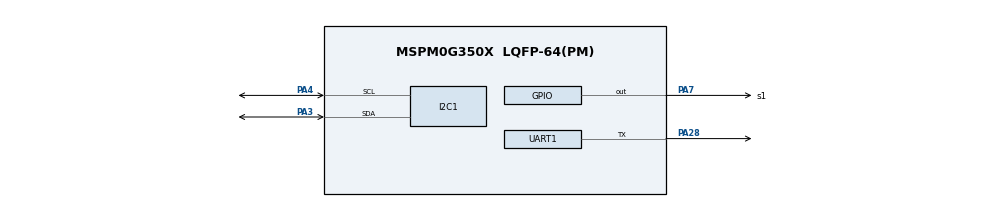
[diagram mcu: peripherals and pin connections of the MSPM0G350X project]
/**
 * @cliArgs --device "MSPM0G350X" --part "Default" --package "LQFP-64(PM)" --product "mspm0_sdk@2.10.00.04"
 * @versions {"tool":"1.27.1+4634"}
 */

/**
 * Import the modules used in this configuration.
 */
const ADC12         = scripting.addModule("/ti/driverlib/ADC12", {}, false);
const ADC121        = ADC12.addInstance();
const ADC122        = ADC12.addInstance();
const GPIO          = scripting.addModule("/ti/driverlib/GPIO", {}, false);
const GPIO1         = GPIO.addInstance();
const I2C           = scripting.addModule("/ti/driverlib/I2C", {}, false);
const I2C1          = I2C.addInstance();
const SYSCTL        = scripting.addModule("/ti/driverlib/SYSCTL");
const TIMER         = scripting.addModule("/ti/driverlib/TIMER", {}, false);
const TIMER1        = TIMER.addInstance();
const UART          = scripting.addModule("/ti/driverlib/UART", {}, false);
const UART1         = UART.addInstance();
const ProjectConfig = scripting.addModule("/ti/project_config/ProjectConfig");

/**
 * Write custom configuration values to the imported modules.
 */
ADC121.samplingOperationMode             = "sequence";
ADC121.endAdd                            = 3;
ADC121.adcMem0chansel                    = "DL_ADC12_INPUT_CHAN_5";
ADC121.adcMem1chansel                    = "DL_ADC12_INPUT_CHAN_6";
ADC121.adcMem2chansel                    = "DL_ADC12_INPUT_CHAN_7";
ADC121.adcMem3chansel                    = "DL_ADC12_INPUT_CHAN_8";
ADC121.enabledInterrupts                 = ["DL_ADC12_INTERRUPT_MEM3_RESULT_LOADED"];
ADC121.$name                             = "ADC12_1";
ADC121.sampClkDiv                        = "DL_ADC12_CLOCK_DIVIDE_48";
ADC121.trigSrc                           = "DL_ADC12_TRIG_SRC_EVENT";
ADC121.subChanID                         = 2;
ADC121.adcMem0_name                      = "s8";
ADC121.adcMem1_name                      = "s7";
ADC121.adcMem2_name                      = "s6";
ADC121.adcMem3_name                      = "s5";
ADC121.adcPin5Config.hideOutputInversion = scripting.forceWrite(false);
ADC121.adcPin5Config.$name               = "ti_driverlib_gpio_GPIOPinGeneric2";
ADC121.adcPin6Config.hideOutputInversion = scripting.forceWrite(false);
ADC121.adcPin6Config.$name               = "ti_driverlib_gpio_GPIOPinGeneric3";
ADC121.adcPin7Config.hideOutputInversion = scripting.forceWrite(false);
ADC121.adcPin7Config.$name               = "ti_driverlib_gpio_GPIOPinGeneric4";
ADC121.adcPin8Config.$name               = "ti_driverlib_gpio_GPIOPinGeneric0";
ADC121.adcPin8Config.hideOutputInversion = scripting.forceWrite(false);

ADC122.samplingOperationMode             = "sequence";
ADC122.endAdd                            = 3;
ADC122.adcMem0_name                      = "s1";
ADC122.adcMem1_name                      = "s2";
ADC122.adcMem1chansel                    = "DL_ADC12_INPUT_CHAN_1";
ADC122.adcMem2_name                      = "s3";
ADC122.adcMem2chansel                    = "DL_ADC12_INPUT_CHAN_2";
ADC122.adcMem3_name                      = "s4";
ADC122.adcMem3chansel                    = "DL_ADC12_INPUT_CHAN_3";
ADC122.enabledInterrupts                 = ["DL_ADC12_INTERRUPT_MEM3_RESULT_LOADED"];
ADC122.$name                             = "ADC12_0";
ADC122.sampClkDiv                        = "DL_ADC12_CLOCK_DIVIDE_48";
ADC122.subChanID                         = 1;
ADC122.trigSrc                           = "DL_ADC12_TRIG_SRC_EVENT";
ADC122.adcPin0Config.$name               = "ti_driverlib_gpio_GPIOPinGeneric1";
ADC122.adcPin0Config.hideOutputInversion = scripting.forceWrite(false);
ADC122.adcPin1Config.hideOutputInversion = scripting.forceWrite(false);
ADC122.adcPin1Config.$name               = "ti_driverlib_gpio_GPIOPinGeneric5";
ADC122.adcPin2Config.hideOutputInversion = scripting.forceWrite(false);
ADC122.adcPin2Config.$name               = "ti_driverlib_gpio_GPIOPinGeneric6";
ADC122.adcPin3Config.hideOutputInversion = scripting.forceWrite(false);
ADC122.adcPin3Config.$name               = "ti_driverlib_gpio_GPIOPinGeneric7";

const Board = scripting.addModule("/ti/driverlib/Board", {}, false);

GPIO1.$name                              = "GPIO_LEDS";
GPIO1.associatedPins.create(9);
GPIO1.associatedPins[0].initialValue     = "SET";
GPIO1.associatedPins[0].internalResistor = "PULL_UP";
GPIO1.associatedPins[0].$name            = "s1";
GPIO1.associatedPins[0].assignedPin      = "7";
GPIO1.associatedPins[0].assignedPort     = "PORTA";
GPIO1.associatedPins[0].pin.$assign      = "PA7";
GPIO1.associatedPins[1].$name            = "s2";
GPIO1.associatedPins[1].initialValue     = "SET";
GPIO1.associatedPins[1].internalResistor = "PULL_UP";
GPIO1.associatedPins[1].assignedPort     = "PORTB";
GPIO1.associatedPins[1].assignedPin      = "2";
GPIO1.associatedPins[2].$name            = "s3";
GPIO1.associatedPins[2].initialValue     = "SET";
GPIO1.associatedPins[2].internalResistor = "PULL_UP";
GPIO1.associatedPins[2].assignedPort     = "PORTB";
GPIO1.associatedPins[2].assignedPin      = "3";
GPIO1.associatedPins[3].$name            = "s4";
GPIO1.associatedPins[3].initialValue     = "SET";
GPIO1.associatedPins[3].internalResistor = "PULL_UP";
GPIO1.associatedPins[3].assignedPort     = "PORTA";
GPIO1.associatedPins[3].assignedPin      = "8";
GPIO1.associatedPins[4].$name            = "s5";
GPIO1.associatedPins[4].initialValue     = "SET";
GPIO1.associatedPins[4].internalResistor = "PULL_UP";
GPIO1.associatedPins[4].assignedPort     = "PORTB";
GPIO1.associatedPins[4].assignedPin      = "6";
GPIO1.associatedPins[5].$name            = "s6";
GPIO1.associatedPins[5].initialValue     = "SET";
GPIO1.associatedPins[5].internalResistor = "PULL_UP";
GPIO1.associatedPins[5].assignedPort     = "PORTA";
GPIO1.associatedPins[5].assignedPin      = "11";
GPIO1.associatedPins[6].$name            = "s7";
GPIO1.associatedPins[6].initialValue     = "SET";
GPIO1.associatedPins[6].internalResistor = "PULL_UP";
GPIO1.associatedPins[6].assignedPort     = "PORTA";
GPIO1.associatedPins[6].assignedPin      = "10";
GPIO1.associatedPins[7].$name            = "s8";
GPIO1.associatedPins[7].initialValue     = "SET";
GPIO1.associatedPins[7].internalResistor = "PULL_UP";
GPIO1.associatedPins[7].assignedPort     = "PORTA";
GPIO1.associatedPins[7].assignedPin      = "9";
GPIO1.associatedPins[8].$name            = "RUN_LED";
GPIO1.associatedPins[8].initialValue     = "SET";
GPIO1.associatedPins[8].internalResistor = "PULL_UP";
GPIO1.associatedPins[8].assignedPort     = "PORTA";
GPIO1.associatedPins[8].assignedPin      = "17";

I2C1.basicEnableController             = true;
I2C1.$name                             = "I2C_1";
I2C1.basicClockSourceDivider           = 8;
I2C1.peripheral.$assign                = "I2C1";
I2C1.peripheral.sdaPin.$assign         = "PA3";
I2C1.peripheral.sclPin.$assign         = "PA4";
I2C1.sdaPinConfig.hideOutputInversion  = scripting.forceWrite(false);
I2C1.sdaPinConfig.onlyInternalResistor = scripting.forceWrite(false);
I2C1.sdaPinConfig.passedPeripheralType = scripting.forceWrite("Digital");
I2C1.sdaPinConfig.$name                = "ti_driverlib_gpio_GPIOPinGeneric9";
I2C1.sdaPinConfig.internalResistor     = "PULL_UP";
I2C1.sclPinConfig.hideOutputInversion  = scripting.forceWrite(false);
I2C1.sclPinConfig.onlyInternalResistor = scripting.forceWrite(false);
I2C1.sclPinConfig.passedPeripheralType = scripting.forceWrite("Digital");
I2C1.sclPinConfig.$name                = "ti_driverlib_gpio_GPIOPinGeneric10";
I2C1.sclPinConfig.internalResistor     = "PULL_UP";

SYSCTL.clockTreeEn = true;

TIMER1.$name                       = "TIMER_0";
TIMER1.enableShadowLoad            = true;
TIMER1.interruptPriority           = "1";
TIMER1.timerClkDiv                 = 8;
TIMER1.event1PublisherChannel      = 1;
TIMER1.event2PublisherChannel      = 2;
TIMER1.timerMode                   = "PERIODIC_UP";
TIMER1.event1ControllerInterruptEn = ["LOAD_EVENT"];
TIMER1.event2ControllerInterruptEn = ["LOAD_EVENT"];
TIMER1.timerPeriod                 = "10 ms";
TIMER1.peripheral.$assign          = "TIMA0";

UART1.$name                        = "UART_0";
UART1.targetBaudRate               = 115200;
UART1.direction                    = "TX";
UART1.txPinConfig.$name            = "ti_driverlib_gpio_GPIOPinGeneric8";
UART1.txPinConfig.enableConfig     = true;
UART1.txPinConfig.internalResistor = "PULL_UP";
UART1.peripheral.$assign           = "UART0";
UART1.peripheral.txPin.$assign     = "PA28";

ProjectConfig.genDisable = true;

/**
 * Pinmux solution for unlocked pins/peripherals. This ensures that minor changes to the automatic solver in a future
 * version of the tool will not impact the pinmux you originally saw.  These lines can be completely deleted in order to
 * re-solve from scratch.
 */
ADC121.peripheral.$suggestSolution           = "ADC1";
ADC121.peripheral.adcPin5.$suggestSolution   = "PB18";
ADC121.peripheral.adcPin6.$suggestSolution   = "PB19";
ADC121.peripheral.adcPin7.$suggestSolution   = "PA21";
ADC121.peripheral.adcPin8.$suggestSolution   = "PA22";
ADC122.peripheral.$suggestSolution           = "ADC0";
ADC122.peripheral.adcPin0.$suggestSolution   = "PA27";
ADC122.peripheral.adcPin1.$suggestSolution   = "PA26";
ADC122.peripheral.adcPin2.$suggestSolution   = "PA25";
ADC122.peripheral.adcPin3.$suggestSolution   = "PA24";
Board.peripheral.$suggestSolution            = "DEBUGSS";
Board.peripheral.swclkPin.$suggestSolution   = "PA20";
Board.peripheral.swdioPin.$suggestSolution   = "PA19";
GPIO1.associatedPins[1].pin.$suggestSolution = "PB2";
GPIO1.associatedPins[2].pin.$suggestSolution = "PB3";
GPIO1.associatedPins[3].pin.$suggestSolution = "PA8";
GPIO1.associatedPins[4].pin.$suggestSolution = "PB6";
GPIO1.associatedPins[5].pin.$suggestSolution = "PA11";
GPIO1.associatedPins[6].pin.$suggestSolution = "PA10";
GPIO1.associatedPins[7].pin.$suggestSolution = "PA9";
GPIO1.associatedPins[8].pin.$suggestSolution = "PA17";
